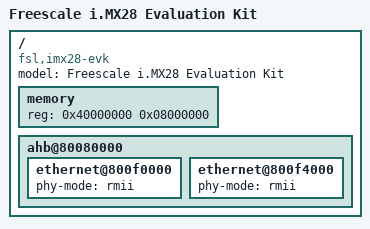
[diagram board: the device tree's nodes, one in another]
/*
 * Copyright 2012 Freescale Semiconductor, Inc.
 *
 * The code contained herein is licensed under the GNU General Public
 * License. You may obtain a copy of the GNU General Public License
 * Version 2 or later at the following locations:
 *
 * http://www.opensource.org/licenses/gpl-license.html
 * http://www.gnu.org/copyleft/gpl.html
 */

/dts-v1/;
/include/ "imx28.dtsi"

/ {
	model = "Freescale i.MX28 Evaluation Kit";
	compatible = "fsl,imx28-evk", "fsl,imx28";

	memory {
		reg = <0x40000000 0x08000000>;
	};

	ahb@80080000 {
		ethernet@800f0000 {
			phy-mode = "rmii";
			status = "okay";
		};

		ethernet@800f4000 {
			phy-mode = "rmii";
			status = "okay";
		};
	};
};
